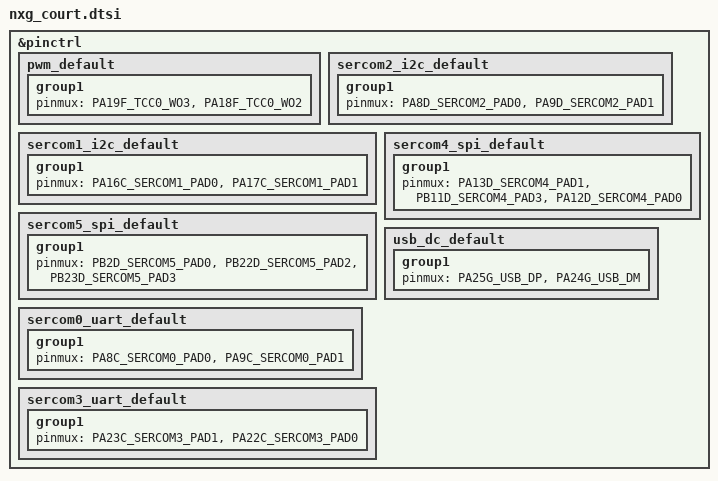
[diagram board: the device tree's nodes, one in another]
#include <dt-bindings/pinctrl/samd21-da1gXabcd-pinctrl.h>

&pinctrl {
	pwm_default: pwm_default {
		group1 {
			pinmux = <PA19F_TCC0_WO3>,
				 <PA18F_TCC0_WO2>;
		};
	};

	sercom2_i2c_default: sercom2_i2c_default {
		group1 {
			pinmux = <PA8D_SERCOM2_PAD0>,
				 <PA9D_SERCOM2_PAD1>;
		};
	};
	sercom1_i2c_default: sercom1_i2c_default {
		group1 {
			pinmux = <PA16C_SERCOM1_PAD0>,
				 <PA17C_SERCOM1_PAD1>;
		};
	};
	sercom4_spi_default: sercom4_spi_default {
		group1 {
			pinmux = <PA13D_SERCOM4_PAD1>,
				 <PB11D_SERCOM4_PAD3>,
				 <PA12D_SERCOM4_PAD0>;
		};
	};
	sercom5_spi_default: sercom5_spi_default {
		group1 {
			pinmux = <PB2D_SERCOM5_PAD0>,
				 <PB22D_SERCOM5_PAD2>,
				 <PB23D_SERCOM5_PAD3>;
		};
	};

	sercom0_uart_default: sercom0_uart_default {
		group1 {
			pinmux = <PA8C_SERCOM0_PAD0>,
				 <PA9C_SERCOM0_PAD1>;
		};
	};
	sercom3_uart_default: sercom3_uart_default {
		group1 {
			pinmux = <PA23C_SERCOM3_PAD1>,
				 <PA22C_SERCOM3_PAD0>;
		};
	};

	usb_dc_default: usb_dc_default {
		group1 {
			pinmux = <PA25G_USB_DP>,
				 <PA24G_USB_DM>;
		};
	};
};
